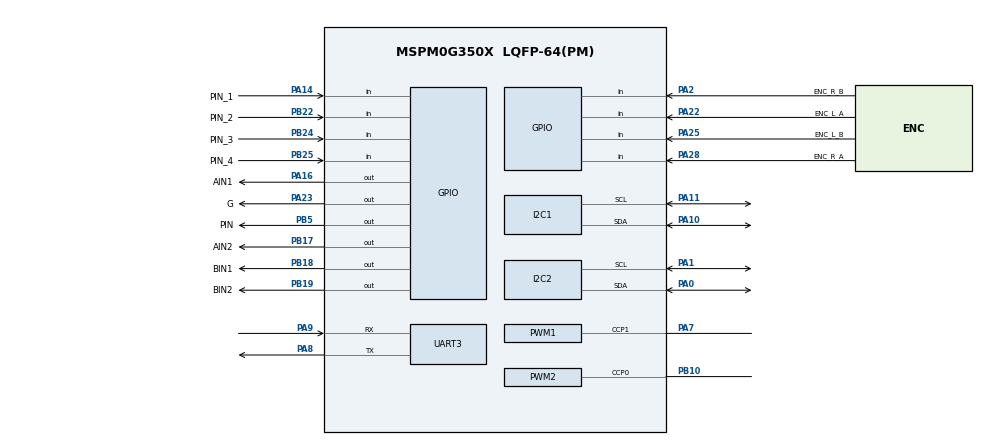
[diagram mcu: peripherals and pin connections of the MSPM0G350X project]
/**
 * @cliArgs --device "MSPM0G350X" --part "Default" --package "LQFP-64(PM)" --product "mspm0_sdk@2.10.00.04"
 * @versions {"tool":"1.27.0+4565"}
 */

/**
 * Import the modules used in this configuration.
 */
const GPIO    = scripting.addModule("/ti/driverlib/GPIO", {}, false);
const GPIO1   = GPIO.addInstance();
const GPIO2   = GPIO.addInstance();
const GPIO5   = GPIO.addInstance();
const GPIO6   = GPIO.addInstance();
const I2C     = scripting.addModule("/ti/driverlib/I2C", {}, false);
const I2C1    = I2C.addInstance();
const I2C2    = I2C.addInstance();
const PWM     = scripting.addModule("/ti/driverlib/PWM", {}, false);
const PWM1    = PWM.addInstance();
const PWM2    = PWM.addInstance();
const SYSCTL  = scripting.addModule("/ti/driverlib/SYSCTL");
const SYSTICK = scripting.addModule("/ti/driverlib/SYSTICK");
const TIMER   = scripting.addModule("/ti/driverlib/TIMER", {}, false);
const TIMER1  = TIMER.addInstance();
const UART    = scripting.addModule("/ti/driverlib/UART", {}, false);
const UART3   = UART.addInstance();

/**
 * Write custom configuration values to the imported modules.
 */
GPIO1.$name                               = "Motor_IO";
GPIO1.associatedPins.create(8);
GPIO1.associatedPins[0].$name             = "AIN1";
GPIO1.associatedPins[0].internalResistor  = "PULL_DOWN";
GPIO1.associatedPins[0].pin.$assign       = "PA16";
GPIO1.associatedPins[1].$name             = "AIN2";
GPIO1.associatedPins[1].internalResistor  = "PULL_DOWN";
GPIO1.associatedPins[1].pin.$assign       = "PB17";
GPIO1.associatedPins[2].$name             = "BIN1";
GPIO1.associatedPins[2].internalResistor  = "PULL_DOWN";
GPIO1.associatedPins[2].pin.$assign       = "PB18";
GPIO1.associatedPins[3].$name             = "BIN2";
GPIO1.associatedPins[3].internalResistor  = "PULL_DOWN";
GPIO1.associatedPins[3].pin.$assign       = "PB19";
GPIO1.associatedPins[4].$name             = "ENC_R_A";
GPIO1.associatedPins[4].direction         = "INPUT";
GPIO1.associatedPins[4].interruptEn       = true;
GPIO1.associatedPins[4].interruptPriority = "0";
GPIO1.associatedPins[4].polarity          = "RISE";
GPIO1.associatedPins[4].inputFilter       = "3_CYCLES";
GPIO1.associatedPins[4].pin.$assign       = "PA28";
GPIO1.associatedPins[5].$name             = "ENC_L_A";
GPIO1.associatedPins[5].direction         = "INPUT";
GPIO1.associatedPins[5].interruptEn       = true;
GPIO1.associatedPins[5].interruptPriority = "0";
GPIO1.associatedPins[5].polarity          = "RISE";
GPIO1.associatedPins[5].inputFilter       = "3_CYCLES";
GPIO1.associatedPins[5].pin.$assign       = "PA22";
GPIO1.associatedPins[6].$name             = "ENC_R_B";
GPIO1.associatedPins[6].direction         = "INPUT";
GPIO1.associatedPins[6].pin.$assign       = "PA2";
GPIO1.associatedPins[7].$name             = "ENC_L_B";
GPIO1.associatedPins[7].direction         = "INPUT";
GPIO1.associatedPins[7].pin.$assign       = "PA25";

const Board = scripting.addModule("/ti/driverlib/Board", {}, false);

GPIO2.$name                              = "Key";
GPIO2.associatedPins.create(4);
GPIO2.associatedPins[0].$name            = "PIN_1";
GPIO2.associatedPins[0].direction        = "INPUT";
GPIO2.associatedPins[0].internalResistor = "PULL_UP";
GPIO2.associatedPins[0].pin.$assign      = "PA14";
GPIO2.associatedPins[1].$name            = "PIN_2";
GPIO2.associatedPins[1].direction        = "INPUT";
GPIO2.associatedPins[1].internalResistor = "PULL_UP";
GPIO2.associatedPins[1].pin.$assign      = "PB22";
GPIO2.associatedPins[2].$name            = "PIN_3";
GPIO2.associatedPins[2].direction        = "INPUT";
GPIO2.associatedPins[2].internalResistor = "PULL_UP";
GPIO2.associatedPins[2].pin.$assign      = "PB24";
GPIO2.associatedPins[3].$name            = "PIN_4";
GPIO2.associatedPins[3].direction        = "INPUT";
GPIO2.associatedPins[3].internalResistor = "PULL_UP";
GPIO2.associatedPins[3].pin.$assign      = "PB25";

GPIO5.$name                         = "LED";
GPIO5.associatedPins.create(1);
GPIO5.associatedPins[0].$name       = "G";
GPIO5.associatedPins[0].pin.$assign = "PA23";

GPIO6.$name                         = "Buzzer";
GPIO6.associatedPins[0].$name       = "PIN";
GPIO6.associatedPins[0].pin.$assign = "PB5";

I2C1.$name                             = "OLED";
I2C1.basicEnableController             = true;
I2C1.basicControllerStandardBusSpeed   = "Fast";
I2C1.peripheral.sdaPin.$assign         = "PA10";
I2C1.peripheral.sclPin.$assign         = "PA11";
I2C1.sdaPinConfig.$name                = "ti_driverlib_gpio_GPIOPinGeneric0";
I2C1.sdaPinConfig.hideOutputInversion  = scripting.forceWrite(false);
I2C1.sdaPinConfig.onlyInternalResistor = scripting.forceWrite(false);
I2C1.sdaPinConfig.passedPeripheralType = scripting.forceWrite("Digital");
I2C1.sclPinConfig.hideOutputInversion  = scripting.forceWrite(false);
I2C1.sclPinConfig.onlyInternalResistor = scripting.forceWrite(false);
I2C1.sclPinConfig.passedPeripheralType = scripting.forceWrite("Digital");
I2C1.sclPinConfig.$name                = "ti_driverlib_gpio_GPIOPinGeneric2";

I2C2.$name                             = "Gray_JY61P_I2C";
I2C2.basicEnableController             = true;
I2C2.basicControllerStandardBusSpeed   = "Fast";
I2C2.intController                     = ["ARBITRATION_LOST","NACK","RXFIFO_TRIGGER","RX_DONE","TX_DONE"];
I2C2.peripheral.$assign                = "I2C0";
I2C2.peripheral.sdaPin.$assign         = "PA0";
I2C2.peripheral.sclPin.$assign         = "PA1";
I2C2.sdaPinConfig.hideOutputInversion  = scripting.forceWrite(false);
I2C2.sdaPinConfig.onlyInternalResistor = scripting.forceWrite(false);
I2C2.sdaPinConfig.passedPeripheralType = scripting.forceWrite("Digital");
I2C2.sdaPinConfig.$name                = "ti_driverlib_gpio_GPIOPinGeneric8";
I2C2.sclPinConfig.hideOutputInversion  = scripting.forceWrite(false);
I2C2.sclPinConfig.onlyInternalResistor = scripting.forceWrite(false);
I2C2.sclPinConfig.passedPeripheralType = scripting.forceWrite("Digital");
I2C2.sclPinConfig.$name                = "ti_driverlib_gpio_GPIOPinGeneric9";

PWM1.$name                              = "Motor_Left";
PWM1.clockDivider                       = 8;
PWM1.timerStartTimer                    = true;
PWM1.pwmMode                            = "EDGE_ALIGN_UP";
PWM1.ccIndex                            = [1];
PWM1.ccp1PinConfig.$name                = "ti_driverlib_gpio_GPIOPinGeneric5";
PWM1.ccp1PinConfig.direction            = scripting.forceWrite("OUTPUT");
PWM1.ccp1PinConfig.hideOutputInversion  = scripting.forceWrite(false);
PWM1.ccp1PinConfig.onlyInternalResistor = scripting.forceWrite(false);
PWM1.ccp1PinConfig.passedPeripheralType = scripting.forceWrite("Digital");
PWM1.peripheral.$assign                 = "TIMA0";
PWM1.peripheral.ccp1Pin.$assign         = "PA7";
PWM1.PWM_CHANNEL_1.$name                = "ti_driverlib_pwm_PWMTimerCC1";
PWM1.PWM_CHANNEL_1.ccValue              = 500;

PWM2.$name                              = "Motor_Right";
PWM2.clockDivider                       = 8;
PWM2.timerStartTimer                    = true;
PWM2.pwmMode                            = "EDGE_ALIGN_UP";
PWM2.ccIndex                            = [0];
PWM2.PWM_CHANNEL_0.$name                = "ti_driverlib_pwm_PWMTimerCC0";
PWM2.PWM_CHANNEL_0.dutyCycle            = 50;
PWM2.ccp0PinConfig.direction            = scripting.forceWrite("OUTPUT");
PWM2.ccp0PinConfig.hideOutputInversion  = scripting.forceWrite(false);
PWM2.ccp0PinConfig.onlyInternalResistor = scripting.forceWrite(false);
PWM2.ccp0PinConfig.passedPeripheralType = scripting.forceWrite("Digital");
PWM2.ccp0PinConfig.$name                = "ti_driverlib_gpio_GPIOPinGeneric4";
PWM2.peripheral.$assign                 = "TIMG0";
PWM2.peripheral.ccp0Pin.$assign         = "PB10";

SYSCTL.forceDefaultClkConfig = true;

SYSTICK.periodEnable    = true;
SYSTICK.interruptEnable = true;
SYSTICK.systickEnable   = true;
SYSTICK.period          = 32000;

TIMER1.$name              = "TIMER_0";
TIMER1.timerClkPrescale   = 100;
TIMER1.timerMode          = "PERIODIC";
TIMER1.interrupts         = ["ZERO"];
TIMER1.timerClkDiv        = 8;
TIMER1.timerStartTimer    = true;
TIMER1.interruptPriority  = "3";
TIMER1.timerPeriod        = "20ms";
TIMER1.peripheral.$assign = "TIMA1";

UART3.$name                            = "Debug_Ex";
UART3.targetBaudRate                   = 115200;
UART3.peripheral.rxPin.$assign         = "PA9";
UART3.peripheral.txPin.$assign         = "PA8";
UART3.txPinConfig.direction            = scripting.forceWrite("OUTPUT");
UART3.txPinConfig.hideOutputInversion  = scripting.forceWrite(false);
UART3.txPinConfig.onlyInternalResistor = scripting.forceWrite(false);
UART3.txPinConfig.passedPeripheralType = scripting.forceWrite("Digital");
UART3.txPinConfig.$name                = "ti_driverlib_gpio_GPIOPinGeneric3";
UART3.rxPinConfig.hideOutputInversion  = scripting.forceWrite(false);
UART3.rxPinConfig.onlyInternalResistor = scripting.forceWrite(false);
UART3.rxPinConfig.passedPeripheralType = scripting.forceWrite("Digital");
UART3.rxPinConfig.$name                = "ti_driverlib_gpio_GPIOPinGeneric7";

/**
 * Pinmux solution for unlocked pins/peripherals. This ensures that minor changes to the automatic solver in a future
 * version of the tool will not impact the pinmux you originally saw.  These lines can be completely deleted in order to
 * re-solve from scratch.
 */
Board.peripheral.$suggestSolution          = "DEBUGSS";
Board.peripheral.swclkPin.$suggestSolution = "PA20";
Board.peripheral.swdioPin.$suggestSolution = "PA19";
I2C1.peripheral.$suggestSolution           = "I2C1";
SYSCTL.peripheral.$suggestSolution         = "SYSCTL";
UART3.peripheral.$suggestSolution          = "UART1";
